# DemoMCU register map
教学示例
Registers are 32-bit, read-write, reset 0x0 unless marked. A register's access mark holds for its fields unless they carry their own. Offsets are from the block's base; lines under a group give offsets from that group; [hi:lo] are bit positions; {n}, {i} and the like mark numbered series; 'fields as' and 'values as' point back to an identical list; <NAME> marks a mode.

## Memory map
0x40020000 GPIOA — General purpose I/O

## GPIOA — General purpose I/O
Base 0x40020000
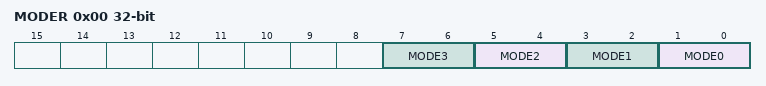
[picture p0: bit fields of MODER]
0x00 MODER — GPIO mode register
  [2n+1:2n] MODE{n} (n=0..3) — Pin mode
    0=Input; 1=Output; 2=Alternate; 3=Analog
0x10 IDR ro — Input data, read-only
  [3:0] DATA
0x14 ODR — Output data
  [3:0] DATA
